# STM32U585 register map
File version: 1.3
CPU: CM33 r0p1, little endian, MPU, FPU, 4 interrupt priority bits
Registers are 32-bit, read-write, reset 0x0 unless marked. A register's access mark holds for its fields unless they carry their own. Offsets are from the block's base; [hi:lo] are bit positions; {n}, {i} and the like mark numbered series.

## EXTI — External interrupt/event controller
Base 0x46022000
Same registers: SEC_EXTI 0x56022000
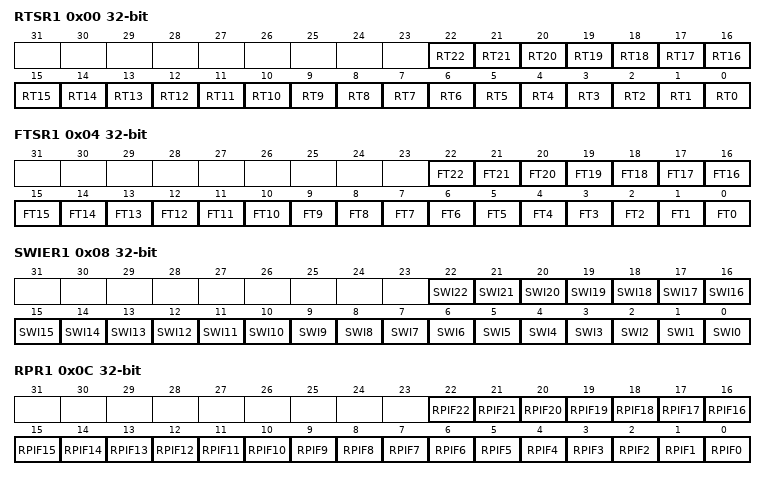
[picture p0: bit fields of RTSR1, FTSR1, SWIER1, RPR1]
0x00 RTSR1 — EXTI rising trigger selection register
  [n] RT{n} (n=0..22) — Rising trigger event configuration bit of configurable event input x
0x04 FTSR1 — EXTI falling trigger selection register
  [n] FT{n} (n=0..22) — Falling trigger event configuration bit of configurable event input x
0x08 SWIER1 — EXTI software interrupt event register
  [n] SWI{n} (n=0..22) — Software interrupt on event x
0x0C RPR1 — EXTI rising edge pending register
  [n] RPIF{n} (n=0..22) — configurable event inputs x rising edge pending bit
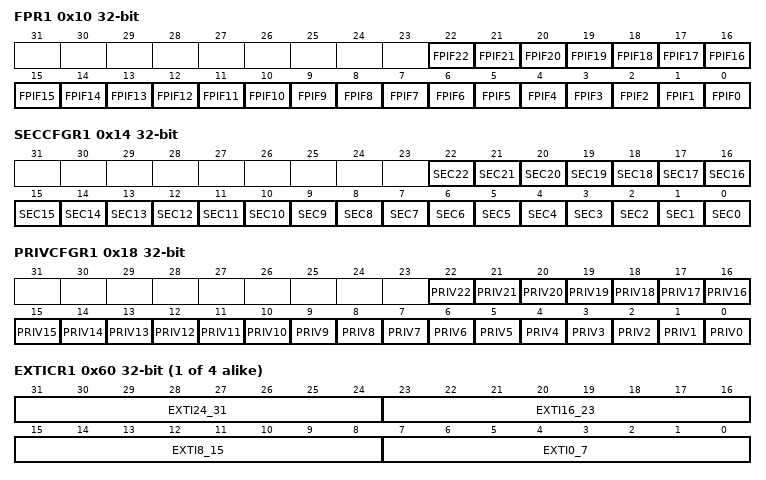
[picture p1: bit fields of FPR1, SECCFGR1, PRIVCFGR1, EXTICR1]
0x10 FPR1 — EXTI falling edge pending register
  [n] FPIF{n} (n=0..22) — configurable event inputs x falling edge pending bit.
0x14 SECCFGR1 — EXTI security configuration register
  [n] SEC{n} (n=0..22) — Security enable on event input x
0x18 PRIVCFGR1 — EXTI privilege configuration register
  [n] PRIV{n} (n=0..22) — Security enable on event input x
{0x5C+4i} EXTICR{i} (i=1..4) — EXTI external interrupt selection register
  [31:24] EXTI24_31 — EXTIm+3 GPIO port selection
  [23:16] EXTI16_23 — EXTIm+2 GPIO port selection
  [15:8] EXTI8_15 — EXTIm+1 GPIO port selection
  [7:0] EXTI0_7 — EXTIm GPIO port selection
0x70 LOCKR — EXTI lock register
  [0] LOCK
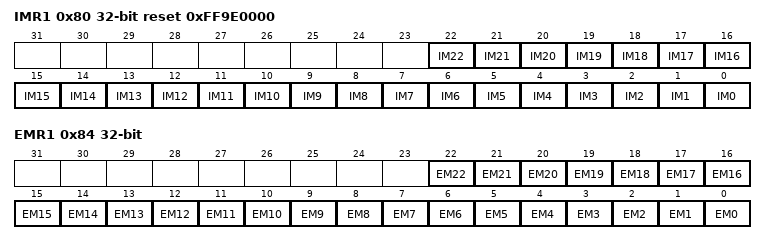
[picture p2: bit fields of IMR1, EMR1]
0x80 IMR1 reset 0xFF9E0000 — EXTI CPU wakeup with interrupt mask register
  [n] IM{n} (n=0..22) — CPU wakeup with interrupt mask on event input
0x84 EMR1 — EXTI CPU wakeup with event mask register
  [n] EM{n} (n=0..22) — CPU wakeup with event generation mask on event input

## ICache
Base 0x40030400
Same registers: SEC_ICache 0x50030400
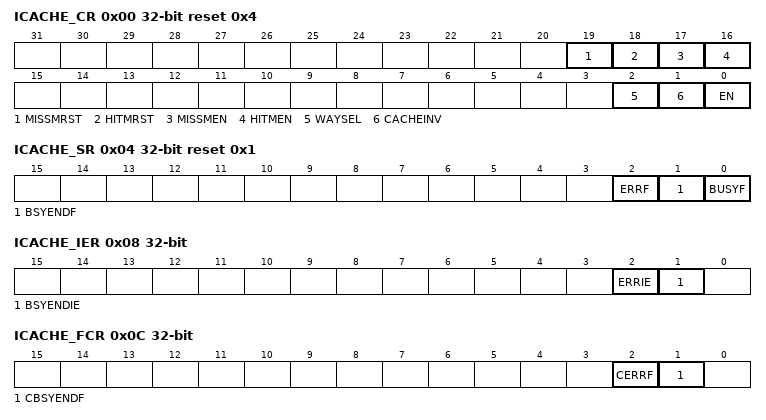
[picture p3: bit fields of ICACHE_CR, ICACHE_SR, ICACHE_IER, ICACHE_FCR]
0x00 ICACHE_CR access per field reset 0x4 — ICACHE control register
  [19] MISSMRST rw, [18] HITMRST rw, [17] MISSMEN rw, [16] HITMEN rw, [2] WAYSEL rw, [1] CACHEINV wo, [0] EN rw
0x04 ICACHE_SR ro reset 0x1 — ICACHE status register
  [2] ERRF, [1] BSYENDF, [0] BUSYF
0x08 ICACHE_IER — ICACHE interrupt enable register
  [2] ERRIE, [1] BSYENDIE
0x0C ICACHE_FCR wo — ICACHE flag clear register
  [2] CERRF, [1] CBSYENDF
0x10 ICACHE_HMONR ro — ICACHE hit monitor register
  [31:0] HITMON
0x14 ICACHE_MMONR ro — ICACHE miss monitor register
  [15:0] MISSMON
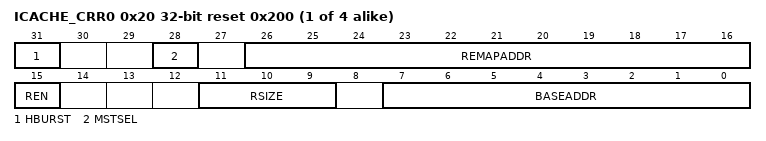
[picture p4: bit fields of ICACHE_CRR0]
{0x20+4i} ICACHE_CRR{i} reset 0x200 (i=0..3) — ICACHE region configuration register
  [31] HBURST, [28] MSTSEL, [26:16] REMAPADDR, [15] REN, [11:9] RSIZE, [7:0] BASEADDR

## DCACHE
Base 0x40031400
Same registers: SEC_DCACHE 0x50031400
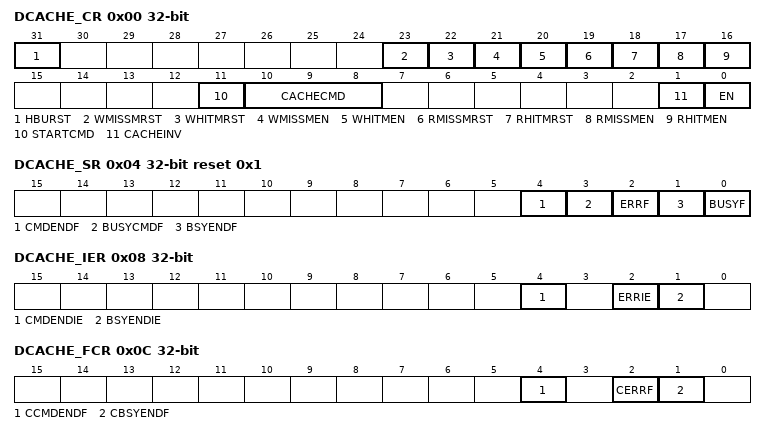
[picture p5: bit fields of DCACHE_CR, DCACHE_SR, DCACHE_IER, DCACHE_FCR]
0x00 DCACHE_CR access per field — DCACHE control register
  [31] HBURST rw, [23] WMISSMRST rw, [22] WHITMRST rw, [21] WMISSMEN rw, [20] WHITMEN rw, [19] RMISSMRST rw, [18] RHITMRST rw, [17] RMISSMEN rw, [16] RHITMEN rw, [11] STARTCMD wo, [10:8] CACHECMD rw, [1] CACHEINV wo, [0] EN rw
0x04 DCACHE_SR ro reset 0x1 — DCACHE status register
  [4] CMDENDF, [3] BUSYCMDF, [2] ERRF, [1] BSYENDF, [0] BUSYF
0x08 DCACHE_IER — DCACHE interrupt enable register
  [4] CMDENDIE, [2] ERRIE, [1] BSYENDIE
0x0C DCACHE_FCR wo — DCACHE flag clear register
  [4] CCMDENDF, [2] CERRF, [1] CBSYENDF
0x10 DCACHE_RHMONR ro — DCACHE read-hit monitor register
  [31:0] RHITMON
0x14 DCACHE_RMMONR ro — DCACHE read-miss monitor register
  [15:0] MRISSMON — RMISSMON
0x20 DCACHE_WHMONR ro — write-hit monitor register
  [31:0] WHITMON
0x24 DCACHE_WMMONR ro — write-miss monitor register
  [15:0] WMISSMON
0x28 DCACHE_CMDRSADDRR — command range start address register
  [31:0] CMDSTARTADDR
0x2C DCACHE_CMDREADDRR — command range start address register
  [31:0] CMDENDADDR

## IWDG — Independent watchdog
Base 0x40003000
Same registers: SEC_IWDG 0x50003000
0x00 KR wo — Key register
  [15:0] KEY — Key value (write only, read 0x0000)
0x04 PR — Prescaler register
  [3:0] PR — Prescaler divider
0x08 RLR reset 0xFFF — Reload register
  [11:0] RL — Watchdog counter reload value
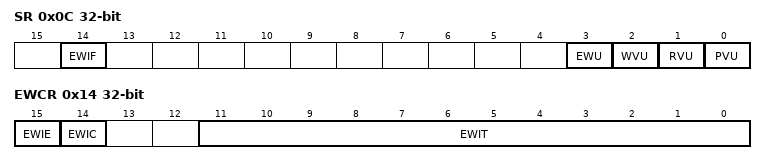
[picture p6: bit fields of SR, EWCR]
0x0C SR ro — Status register
  [14] EWIF — Watchdog Early interrupt flag
  [3] EWU — Watchdog interrupt comparator value update
  [2] WVU — Watchdog counter window value update
  [1] RVU — Watchdog counter reload value update
  [0] PVU — Watchdog prescaler value update
0x10 WINR reset 0xFFF — Window register
  [11:0] WIN — Watchdog counter window value
0x14 EWCR — IWDG early wakeup interrupt register
  [15] EWIE — Watchdog early interrupt enable
  [14] EWIC — Watchdog early interrupt acknowledge
  [11:0] EWIT — Watchdog counter window value
